# Musca_S1 register map
Vendor: ARM Ltd.; Series: ARMv8-M Mainline; File version: 1.0
CPU: CM33 r0p1, little endian, MPU, no FPU, 3 interrupt priority bits, 8 SAU regions
Registers are 32-bit, read-write, reset 0x0 unless marked. A register's access mark holds for its fields unless they carry their own. Offsets are from the block's base; [hi:lo] are bit positions.

## UART0
Base 0x40101000
Same registers: UART1 0x40102000, UART0_Secure 0x50101000, UART1_Secure 0x50102000
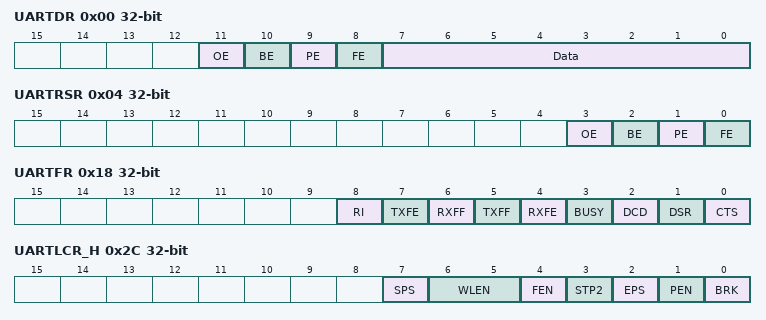
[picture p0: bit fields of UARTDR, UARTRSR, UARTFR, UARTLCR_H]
0x00 UARTDR — Data Register
  [11] OE — Overrun error: Indicates if data is received and the receive FIFO is already full
  [10] BE — Break error: Indicates that the received data input was held LOW for longer than a full-word transmission time
  [9] PE — Parity error: Indicates that the parity of the received data character does not match the parity selected
  [8] FE — Framing error: Indicates the received character did not had a valid stop bit
  [7:0] Data — Receive/Transmit data
0x04 UARTRSR (alternate view of UARTECR) — Receive status register/error clear Register
  [3] OE — Overrunerror: Indicates if data is received and the receive FIFO is already full
  [2] BE — Break error: Indicates that the received data input was held LOW for longer than a full-word transmission time
  [1] PE — Parity error: Indicates that the parity of the received data character does not match the parity selected
  [0] FE — Framing error: Indicates the received character did not had a valid stop bit
0x18 UARTFR ro — Flag Register
  [8] RI — Ring indicator
  [7] TXFE — Transmit FIFO empty
  [6] RXFF — Receive FIFO full
  [5] TXFF — Transmit FIFO full
  [4] RXFE — Receive FIFO empty
  [3] BUSY — UART busy
  [2] DCD — Data carrier detect
  [1] DSR — Data set ready
  [0] CTS — Clear to send
0x20 UARTILPR — IrDA low-power counter Register
  [7:0] ILPDVSR — 8-bit low-power divisor value
0x24 UARTIBRD — Integer baud rate Register
  [15:0] BAUD_DIVINT — The integer baud rate divisor
0x28 UARTFBRD — Fractional baud rate Register
  [5:0] BAUD_DIVINT — The integer baud rate divisor
0x2C UARTLCR_H — Line control Register
  [7] SPS — Stick parity select
  [6:5] WLEN — Word length
  [4] FEN — Enable FIFOs
  [3] STP2 — Two stop bits select
  [2] EPS — Even parity select
  [1] PEN — Parity enable
  [0] BRK — Send break
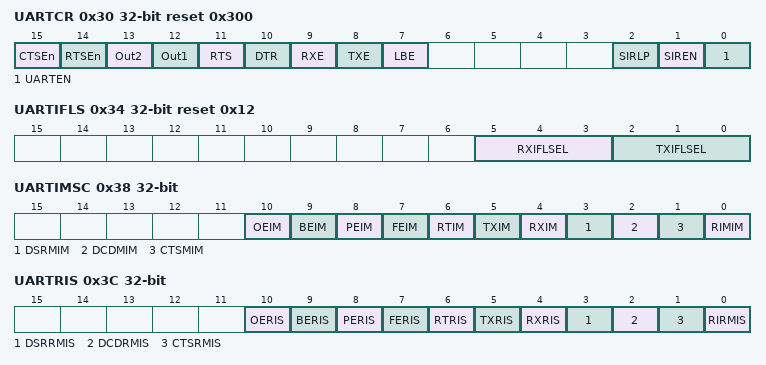
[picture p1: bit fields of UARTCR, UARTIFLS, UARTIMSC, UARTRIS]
0x30 UARTCR reset 0x300 — Control Register
  [15] CTSEn — CTS hardware flow control enable
    0=Disable (CTS hardware flow control is disabled); 1=Enable (CTS hardware flow control is enabled)
  [14] RTSEn — RTS hardware flow control enable
    0=Disable (RTS hardware flow control is disabled); 1=Enable (RTS hardware flow control is enabled)
  [13] Out2 — Complement of the UART Out2
  [12] Out1 — Complement of the UART Out1
  [11] RTS — Request to send
  [10] DTR — Data transmit ready
  [9] RXE — Receive enable
    0=Disable (Reception is disabled); 1=Enable (Reception is enabled)
  [8] TXE — Transmit enable
    0=Disable (Transmission is disabled); 1=Enable (Transmission is enabled)
  [7] LBE — Loop back enable
    0=Disable (Loop back mode is disabled); 1=Enable (Loop back mode is enabled)
  [2] SIRLP — IrDA SIR low power mode
    0=Disable (SIR low power mode is disabled); 1=Enable (SIR low power mode is enabled)
  [1] SIREN — SIR enable
    0=Disable (SIR is disabled); 1=Enable (SIR is enabled)
  [0] UARTEN — UART enable
    0=Disable (UART is disabled); 1=Enable (UART is enabled)
0x34 UARTIFLS reset 0x12 — Interrupt FIFO level select Register
  [5:3] RXIFLSEL — Receive interrupt FIFO level select
    0=1/8 full (Receive FIFO becomes greater than or equal to 1/8 full); 1=1/4 full (Receive FIFO becomes greater than or equal to 1/4 full); 2=1/2 full (Receive FIFO becomes greater than or equal to 1/2 full); 3=3/4 full (Receive FIFO becomes greater than or equal to 3/4 full); 4=7/8 full (Receive FIFO becomes greater than or equal to 7/8 full)
  [2:0] TXIFLSEL — Transmit interrupt FIFO level select
    0=1/8 full (Transmit FIFO becomes less than or equal to 1/8 full); 1=1/4 full (Transmit FIFO becomes less than or equal to 1/4 full); 2=1/2 full (Transmit FIFO becomes less than or equal to 1/2 full); 3=3/4 full (Transmit FIFO becomes less than or equal to 3/4 full); 4=7/8 full (Transmit FIFO becomes less than or equal to 7/8 full)
0x38 UARTIMSC — Interrupt mask set/clear Register
  [all] fields
    0=Clears the mask; 1=Set (Sets the mask)
  [10] OEIM — Overrun error interrupt mask
  [9] BEIM — Break error interrupt mask
  [8] PEIM — Parity error interrupt mask
  [7] FEIM — Framing error interrupt mask
  [6] RTIM — Receive timeout interrupt mask
  [5] TXIM — Transmit interrupt mask
  [4] RXIM — Receive interrupt mask
  [3] DSRMIM — nUARTDSR modem interrupt mask
  [2] DCDMIM — nUARTDCD modem interrupt mask
  [1] CTSMIM — nUARTCTS modem interrupt mask
  [0] RIMIM — nUARTRI modem interrupt mask
0x3C UARTRIS ro — Raw interrupt status Register
  [10] OERIS — Overrun error interrupt status
  [9] BERIS — Break error interrupt status
  [8] PERIS — Parity error interrupt status
  [7] FERIS — Framing error interrupt status
  [6] RTRIS — Receive timeout interrupt status
  [5] TXRIS — Transmit interrupt status
  [4] RXRIS — Receive interrupt status
  [3] DSRRMIS — nUARTDSR modem interrupt status
  [2] DCDRMIS — nUARTDCD modem interrupt status
  [1] CTSRMIS — nUARTCTS modem interrupt status
  [0] RIRMIS — nUARTRI modem interrupt status
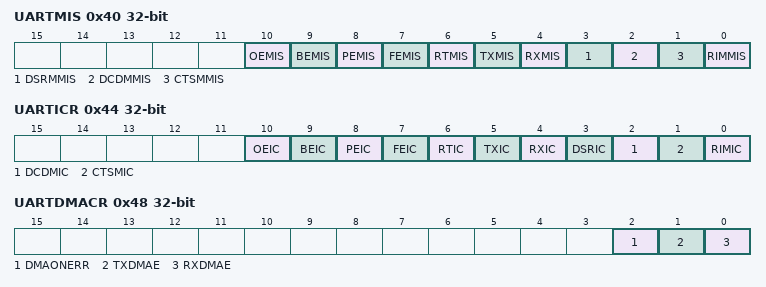
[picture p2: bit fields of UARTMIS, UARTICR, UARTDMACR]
0x40 UARTMIS ro — Masked interrupt status Register
  [10] OEMIS — Overrun error masked interrupt status
  [9] BEMIS — Break error masked interrupt status
  [8] PEMIS — Parity error masked interrupt status
  [7] FEMIS — Framing error masked interrupt status
  [6] RTMIS — Receive timeout masked interrupt status
  [5] TXMIS — Transmit masked interrupt status
  [4] RXMIS — Receive masked interrupt status
  [3] DSRMMIS — nUARTDSR modem masked interrupt status
  [2] DCDMMIS — nUARTDCD modem masked interrupt status
  [1] CTSMMIS — nUARTCTS modem masked interrupt status
  [0] RIMMIS — nUARTRI modem masked interrupt status
0x44 UARTICR wo — Interrupt clear Register
  [10] OEIC — Overrun error interrupt clear, write 1 to clear, write 0 has no effect
  [9] BEIC — Break error interrupt clear, write 1 to clear, write 0 has no effect
  [8] PEIC — Parity error interrupt clear, write 1 to clear, write 0 has no effect
  [7] FEIC — Framing error interrupt clear, write 1 to clear, write 0 has no effect
  [6] RTIC — Receive timeout interrupt clear, write 1 to clear, write 0 has no effect
  [5] TXIC — Transmit interrupt clear, write 1 to clear, write 0 has no effect
  [4] RXIC — Receive interrupt clear, write 1 to clear, write 0 has no effect
  [3] DSRIC — nUARTDSR modem interrupt clear, write 1 to clear, write 0 has no effect
  [2] DCDMIC — nUARTDCD modem interrupt clear, write 1 to clear, write 0 has no effect
  [1] CTSMIC — nUARTCTS modem interrupt clear, write 1 to clear, write 0 has no effect
  [0] RIMIC — nUARTRI modem interrupt clear, write 1 to clear, write 0 has no effect
0x48 UARTDMACR — DMA control Register
  [2] DMAONERR — DMA on error
    0=Disable (DMA receive request outputs are enabled when the UART error interrupt is asserted); 1=Enable (DMA receive request outputs are disabled when the UART error interrupt is asserted)
  [1] TXDMAE — Transmit DMA enable
    0=Disable (Transmit DMA is disabled); 1=Enable (Transmit DMA is enabled)
  [0] RXDMAE — Receive DMA enable
    0=Disable (Receive DMA is disabled); 1=Enable (Receive DMA is enabled)

## Notices in the file
Copyright (C) 2012-2019 Arm Limited. All rights reserved.
Purpose: System Viewer Description (SVD) Example (Schema Version 1.1)
This is a description of a none-existent and incomplete device
for demonstration purposes only.
Redistribution and use in source and binary forms, with or without
modification, are permitted provided that the following conditions are met:
- Redistributions of source code must retain the above copyright
notice, this list of conditions and the following disclaimer.
- Redistributions in binary form must reproduce the above copyright
notice, this list of conditions and the following disclaimer in the
documentation and/or other materials provided with the distribution.
- Neither the name of ARM nor the names of its contributors may be used
to endorse or promote products derived from this software without
specific prior written permission.
THIS SOFTWARE IS PROVIDED BY THE COPYRIGHT HOLDERS AND CONTRIBUTORS "AS IS"
AND ANY EXPRESS OR IMPLIED WARRANTIES, INCLUDING, BUT NOT LIMITED TO, THE
IMPLIED WARRANTIES OF MERCHANTABILITY AND FITNESS FOR A PARTICULAR PURPOSE
ARE DISCLAIMED. IN NO EVENT SHALL COPYRIGHT HOLDERS AND CONTRIBUTORS BE
LIABLE FOR ANY DIRECT, INDIRECT, INCIDENTAL, SPECIAL, EXEMPLARY, OR
CONSEQUENTIAL DAMAGES (INCLUDING, BUT NOT LIMITED TO, PROCUREMENT OF
SUBSTITUTE GOODS OR SERVICES; LOSS OF USE, DATA, OR PROFITS; OR BUSINESS
INTERRUPTION) HOWEVER CAUSED AND ON ANY THEORY OF LIABILITY, WHETHER IN
CONTRACT, STRICT LIABILITY, OR TORT (INCLUDING NEGLIGENCE OR OTHERWISE)
ARISING IN ANY WAY OUT OF THE USE OF THIS SOFTWARE, EVEN IF ADVISED OF THE
POSSIBILITY OF SUCH DAMAGE.
